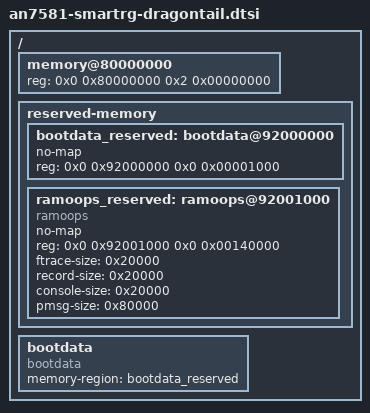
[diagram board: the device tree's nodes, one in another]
// SPDX-License-Identifier: (GPL-2.0-only OR BSD-2-Clause)

/ {

	memory@80000000 {
		device_type = "memory";
		reg = <0x0 0x80000000 0x2 0x00000000>;
	};

	reserved-memory {
		#address-cells = <2>;
		#size-cells = <2>;
		ranges;

		bootdata_reserved: bootdata@92000000 {
			no-map;
			reg = <0x0 0x92000000 0x0 0x00001000>;
		};

		ramoops_reserved: ramoops@92001000 {
			no-map;
			compatible = "ramoops";
			reg = <0x0 0x92001000 0x0 0x00140000>;
			ftrace-size = <0x20000>;
			record-size = <0x20000>;
			console-size = <0x20000>;
			pmsg-size = <0x80000>;
		};
	};

	bootdata {
		compatible = "bootdata";
		memory-region = <&bootdata_reserved>;
	};
};
